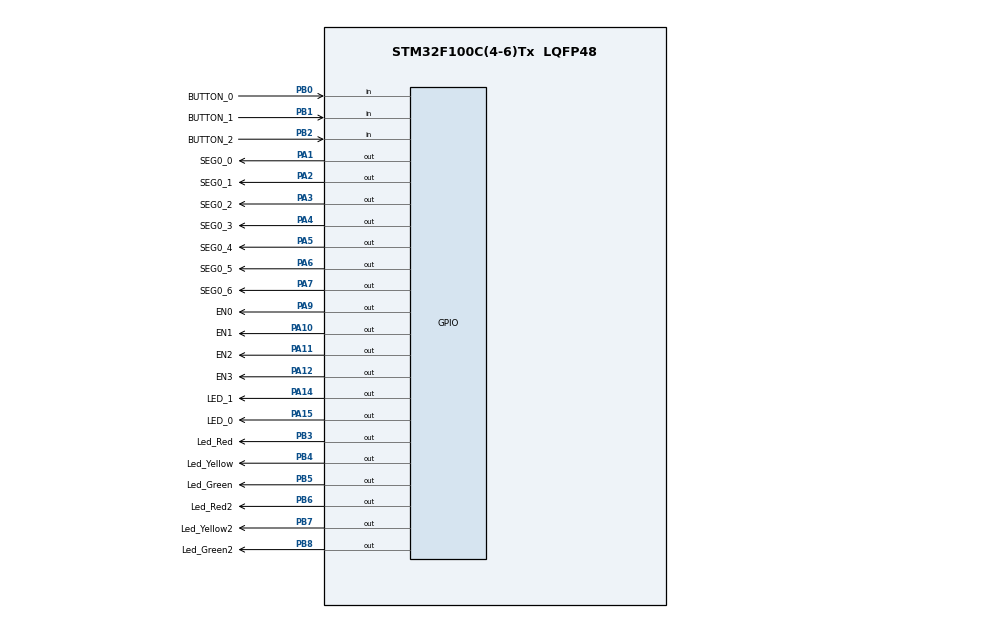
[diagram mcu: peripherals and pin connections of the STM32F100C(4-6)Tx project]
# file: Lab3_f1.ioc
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Mcu.Family=STM32F1
Mcu.Name=STM32F100C(4-6)Tx
Mcu.Package=LQFP48
NVIC.PriorityGroup=NVIC_PRIORITYGROUP_4
NVIC.TIM2_IRQn=true\:0\:0\:false\:false\:true\:true\:true\:true
PA1.GPIO_Label=SEG0_0
PA1.Signal=GPIO_Output
PA10.GPIO_Label=EN1
PA10.Signal=GPIO_Output
PA11.GPIO_Label=EN2
PA11.Signal=GPIO_Output
PA12.GPIO_Label=EN3
PA12.Signal=GPIO_Output
PA14.GPIO_Label=LED_1
PA14.Signal=GPIO_Output
PA15.GPIO_Label=LED_0
PA15.Signal=GPIO_Output
PA2.GPIO_Label=SEG0_1
PA2.Signal=GPIO_Output
PA3.GPIO_Label=SEG0_2
PA3.Signal=GPIO_Output
PA4.GPIO_Label=SEG0_3
PA4.Signal=GPIO_Output
PA5.GPIO_Label=SEG0_4
PA5.Signal=GPIO_Output
PA6.GPIO_Label=SEG0_5
PA6.Signal=GPIO_Output
PA7.GPIO_Label=SEG0_6
PA7.Signal=GPIO_Output
PA9.GPIO_Label=EN0
PA9.Signal=GPIO_Output
PB0.GPIO_Label=BUTTON_0
PB0.GPIO_PuPd=GPIO_PULLUP
PB0.Signal=GPIO_Input
PB1.GPIO_Label=BUTTON_1
PB1.GPIO_PuPd=GPIO_PULLUP
PB1.Signal=GPIO_Input
PB2.GPIO_Label=BUTTON_2
PB2.GPIO_PuPd=GPIO_PULLUP
PB2.Signal=GPIO_Input
PB3.GPIO_Label=Led_Red
PB3.Signal=GPIO_Output
PB4.GPIO_Label=Led_Yellow
PB4.Signal=GPIO_Output
PB5.GPIO_Label=Led_Green
PB5.Signal=GPIO_Output
PB6.GPIO_Label=Led_Red2
PB6.Signal=GPIO_Output
PB7.GPIO_Label=Led_Yellow2
PB7.Signal=GPIO_Output
PB8.GPIO_Label=Led_Green2
PB8.Signal=GPIO_Output
ProjectManager.HeapSize=0x200
ProjectManager.StackSize=0x400
ProjectManager.TargetToolchain=STM32CubeIDE
RCC.APB1Freq_Value=8000000
RCC.APB2Freq_Value=8000000
TIM2.Period=9
TIM2.Prescaler=7999
VP_SYS_VS_ND.Mode=No_Debug
VP_TIM2_VS_ClockSourceINT.Mode=Internal
board=custom

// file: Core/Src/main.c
/* USER CODE BEGIN Header */
/**
  ******************************************************************************
  * @file           : main.c
  * @brief          : Main program body
  ******************************************************************************
  * @attention
  *
  * Copyright (c) 2024 STMicroelectronics.
  * All rights reserved.
  *
  * This software is licensed under terms that can be found in the LICENSE file
  * in the root directory of this software component.
  * If no LICENSE file comes with this software, it is provided AS-IS.
  *
  ******************************************************************************
  */
/* USER CODE END Header */
#include "main.h"
#include "tim.h"
#include "gpio.h"

/* USER CODE BEGIN Includes */
#include "software_timer.h"
#include "button.h"
#include "traffic_light.h"
#include "global.h"
/* USER CODE END Includes */

void SystemClock_Config(void);

int main(void)
{

  /* MCU Configuration--------------------------------------------------------*/

  /* Reset of all peripherals, Initializes the Flash interface and the Systick. */
  HAL_Init();

  /* Configure the system clock */
  SystemClock_Config();

  /* Initialize all configured peripherals */
  MX_GPIO_Init();
  MX_TIM2_Init();
  /* USER CODE BEGIN 2 */

  init_button();
  System_scan_value_led_init();

  /* USER CODE END 2 */

  /* Infinite loop */
  while (1)
  {

    /* USER CODE BEGIN 3 */
	  main_fsm_run();

  }
  /* USER CODE END 3 */
}

void SystemClock_Config(void)
{
  RCC_OscInitTypeDef RCC_OscInitStruct = {0};
  RCC_ClkInitTypeDef RCC_ClkInitStruct = {0};

  /** Initializes the RCC Oscillators according to the specified parameters
  * in the RCC_OscInitTypeDef structure.
  */
  RCC_OscInitStruct.OscillatorType = RCC_OSCILLATORTYPE_HSI;
  RCC_OscInitStruct.HSIState = RCC_HSI_ON;
  RCC_OscInitStruct.HSICalibrationValue = RCC_HSICALIBRATION_DEFAULT;
  RCC_OscInitStruct.PLL.PLLState = RCC_PLL_NONE;
  if (HAL_RCC_OscConfig(&RCC_OscInitStruct) != HAL_OK)
  {
    Error_Handler();
  }

  /** Initializes the CPU, AHB and APB buses clocks
  */
  RCC_ClkInitStruct.ClockType = RCC_CLOCKTYPE_HCLK|RCC_CLOCKTYPE_SYSCLK
                              |RCC_CLOCKTYPE_PCLK1|RCC_CLOCKTYPE_PCLK2;
  RCC_ClkInitStruct.SYSCLKSource = RCC_SYSCLKSOURCE_HSI;
  RCC_ClkInitStruct.AHBCLKDivider = RCC_SYSCLK_DIV1;
  RCC_ClkInitStruct.APB1CLKDivider = RCC_HCLK_DIV1;
  RCC_ClkInitStruct.APB2CLKDivider = RCC_HCLK_DIV1;

  if (HAL_RCC_ClockConfig(&RCC_ClkInitStruct, FLASH_LATENCY_0) != HAL_OK)
  {
    Error_Handler();
  }
}

void Error_Handler(void)
{
  __disable_irq();
  while (1)
  {
  }
}
